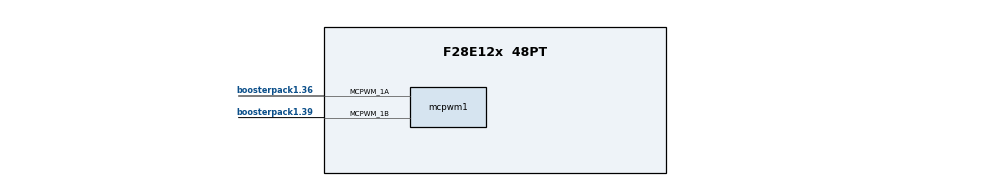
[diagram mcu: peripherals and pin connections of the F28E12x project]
/**
 * @cliArgs --board "/boards/LAUNCHXL_F28E12X" --device "F28E12x" --part "F28E12x_48PT" --package "48PT" --product "C2000WARE@6.00.00.00"
 * @versions {"tool":"1.23.999+220"}
 */

/**
 * Import the modules used in this configuration.
 */
const adc              = scripting.addModule("/driverlib/adc.js", {}, false);
const adc1             = adc.addInstance();
const analog           = scripting.addModule("/driverlib/analog.js", {}, false);
const analog1          = analog.addInstance();
const asysctl          = scripting.addModule("/driverlib/asysctl.js");
const led              = scripting.addModule("/driverlib/board_components/led", {}, false);
const led1             = led.addInstance();
const ecap             = scripting.addModule("/driverlib/ecap.js", {}, false);
const ecap1            = ecap.addInstance();
const inputxbar        = scripting.addModule("/driverlib/inputxbar.js", {}, false);
const inputxbar1       = inputxbar.addInstance();
const inputxbar_input  = scripting.addModule("/driverlib/inputxbar_input.js");
const inputxbar_input1 = inputxbar_input.addInstance();
const mcpwm            = scripting.addModule("/driverlib/mcpwm.js", {}, false);
const mcpwm1           = mcpwm.addInstance();
const mcpwm2           = mcpwm.addInstance();

/**
 * Write custom configuration values to the imported modules.
 */
adc1.$name                          = "myADC0";
adc1.adcClockPrescaler              = "ADC_CLK_DIV_4_0";
adc1.enabledSOCs                    = ["ADC_SOC_NUMBER0"];
adc1.enabledInts                    = ["ADC_INT_NUMBER1"];
adc1.enableInterrupt1               = true;
adc1.enableInterrupt1ContinuousMode = true;
adc1.registerInterrupts             = ["1"];
adc1.soc0SampleWindow               = 8;
adc1.interruptPulseMode             = "ADC_PULSE_END_OF_CONV";
adc1.soc0Trigger                    = "ADC_TRIGGER_MCPWM3_SOCA";
adc1.adcInt1.interruptHandler       = "adcA1ISR";
adc1.adcInt1.enableInterrupt        = true;

analog1.$name            = "myANALOGPinMux0";
adc1.analog              = analog1;
analog1.useCase          = "CUSTOM";
analog1.useInterfacePins = ["A0/CMP3_LITE_DACL/PGA1_INM2"];

asysctl.analogReference = "INTERNAL";

led1.$name          = "myBoardLED0";
led1.gpio.$hardware = system.deviceData.board.components.LED5;

ecap1.$name                    = "myECAP0";
ecap1.eventStop                = "ECAP_EVENT_4";
ecap1.eventTwoPolarity         = "ECAP_EVNT_FALLING_EDGE";
ecap1.eventFourPolarity        = "ECAP_EVNT_FALLING_EDGE";
ecap1.registerInterrupts       = true;
ecap1.enableInterrupt          = true;
ecap1.interruptSourceCapture   = ["ECAP_ISR_SOURCE_CAPTURE_EVENT_3"];
ecap1.ecapInput                = "ECAP_INPUT_INPUTXBAR7";
ecap1.ecapInt.interruptHandler = "ecap1ISR";
ecap1.ecapInt.enableInterrupt  = true;

inputxbar1.$name = "myINPUTXBAR0";

inputxbar_input1.$name          = "myINPUTXBARINPUT0";
inputxbar_input1.inputxbarInput = "XBAR_INPUT7";
inputxbar_input1.inputxbarGpio  = "GPIO4";

mcpwm1.$name                                                         = "myMCPWM0";
mcpwm1.mcpwmTimebase_counterMode                                     = "MCPWM_COUNTER_MODE_UP_DOWN";
mcpwm1.mcpwmCounterCompare_cmpA                                      = 18750;
mcpwm1.mcpwmActionQualifier_MCPWM_AQ_OUTPUT_1A_ON_TIMEBASE_UP_CMPA   = "MCPWM_AQ_OUTPUT_HIGH";
mcpwm1.mcpwmActionQualifier_MCPWM_AQ_OUTPUT_1A_ON_TIMEBASE_DOWN_CMPA = "MCPWM_AQ_OUTPUT_LOW";
mcpwm1.useCase                                                       = "2CH";
mcpwm1.mcpwmTimebase_period                                          = 40000;
mcpwm1.mcpwmTimebase_clockDiv                                        = "MCPWM_CLOCK_DIVIDER_2";
mcpwm1.mcpwm.$assign                                                 = "MCPWM1";
mcpwm1.mcpwm.mcpwm_1aPin.$assign                                     = "boosterpack1.36";
mcpwm1.mcpwm.mcpwm_1bPin.$assign                                     = "boosterpack1.39";

mcpwm2.$name                                               = "myMCPWM1";
mcpwm2.mcpwmTimebase_period                                = 1999;
mcpwm2.mcpwmTimebase_counterMode                           = "MCPWM_COUNTER_MODE_UP";
mcpwm2.mcpwmEventTrigger_MCPWM_SOC_A_triggerEnable         = true;
mcpwm2.mcpwmEventTrigger_MCPWM_SOC_A_triggerSource         = "MCPWM_SOC_TBCTR_PERIOD";
mcpwm2.mcpwmEventTrigger_MCPWM_SOC_A_triggerEventPrescalar = "1";
mcpwm2.useCase                                             = "CUSTOM";
mcpwm2.mcpwm.$assign                                       = "MCPWM3";
